# DSC28034 register map
Vendor: Beijing Haawking Technology Co.,Ltd.; File version: 1.0
Registers are 32-bit, read-write, reset 0x0 unless marked. A register's access mark holds for its fields unless they carry their own. Offsets are from the block's base; [hi:lo] are bit positions; {n}, {i} and the like mark numbered series; 'fields as' and 'values as' point back to an identical list.

## AES — AES Accelerator
Base 0x50450000
{0x0+4i} key[{i}] (i=0..3) — 1st-4th word of key
0x10 encrypt_sel — Encryption or decryption select
  [0] encrypt_sel — Select encryption or decryption mode
    0=encryption (Sets encryption mode); 1=decryption (Sets decryption mode)
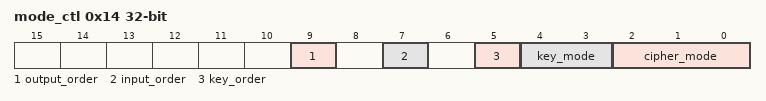
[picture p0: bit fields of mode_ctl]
0x14 mode_ctl — AES mode register
  [9] output_order — Output data order
    0=be (Big Endian); 1=le (Little Endian)
  [7] input_order — Input data order
    0=be (Big Endian); 1=le (Little Endian)
  [5] key_order — Input key order
    0=be (Big Endian); 1=le (Little Endian)
  [4:3] key_mode
    0=AES128; 1=AES192; 2=AES256
  [2:0] cipher_mode
    0=ECB (Electronic Codebook); 1=CBC (Cipher Block Chaining); 2=GCM (Galois/Counter Mode)
{0x18+4i} iv[{i}] (i=0..3) — Initialisation Vector (96 bit for GCM, 128 bit for CBC)
0x28 endian — Endian control
  [0] endian — Input data endian
    0=be (Big Endian); 1=le (Little Endian)
0x2C finish — Finished status
  [0] finish — AES operation finished status
    0=not_finished (Operation not finished); 1=finished (Operation finished)
0x30 dma_sel — DMA select
  [0] dma_sel — Output to DMA if set, to CPU otherwise
0x34 aad_num — GCM additional authenticated data count in bytes, minus one
0x3C pc_num — Plaintext/ciphertext input data count in bytes, minus one
0x40 text_data — Plaintext/ciphertext input data
0x44 aad_data — Additional authenticated data
0x48 tag_chk — Tag check status
  [1:0] tag_chk
    0=busy (Check not finished); 1=fail (Check failed); 2=success (Check success)
0x4C data_in_flag — Data can input flag
  [0] data_in_flag — Data can be written to text_data or aad_data when this flag is set
    0=cannot_input; 1=can_input
{0x50+4i} gcm_in_tag[{i}] (i=0..3) — GCM input tag for comparison with the calculated tag
0x60 out_data — Plaintext/ciphertext output data
0x64 en — AES module enable
  [0] en
    0=Disable module; 1=Enable module
0x68 data_out_flag — Data can output flag
  [0] data_out_flag — Data can be read from out_data when this flag is set
    0=cannot_output (Data cannot output); 1=can_output (Data can output)
0x6C tag_in_flag — Can input tag (when using GCM)
  [0] tag_in_flag — GCM tag can be written to gcm_in_tag when this flag is set
    0=cannot_input; 1=can_input
0x70 tag_clear — Tag clear (a write to this register clears the tag_chk status)
{0x74+4i} gcm_out_tag[{i}] (i=0..3) — Computed GCM output tag
{0x84+4i} key_ext[{i}] (i=0..3) — 5th-8th word of key

## RTC — Real Time Clock
Base 0x50460000
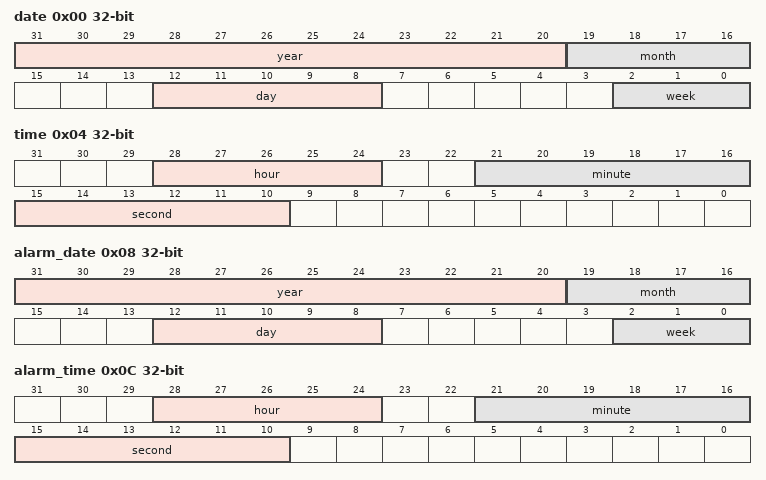
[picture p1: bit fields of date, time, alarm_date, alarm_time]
0x00 date — Timer date information
  [31:20] year range 0..99 — Year. Range [0,99]
  [19:16] month range 1..12 — Month. Range [1,12]
  [12:8] day range 1..31 — Day. Range [1,31] or [1,30] or [1,29] or [1,28]
  [2:0] week range 0..6 — Week. Range [0,6]. 0 is Sunday.
0x04 time — Timer time information
  [28:24] hour range 0..23 — Hour. Range [0,23]
  [21:16] minute range 0..59 — Minute. Range [0,59]
  [15:10] second range 0..59 — Second. Range [0,59]
0x08 alarm_date — Alarm date information
  fields as date
0x0C alarm_time — Alarm time information
  fields as time
0x10 initial_count — Timer counter initial value
  [31:0] count — RTC counter initial value
0x14 current_count — Timer counter current value
  [31:0] count — RTC counter current value
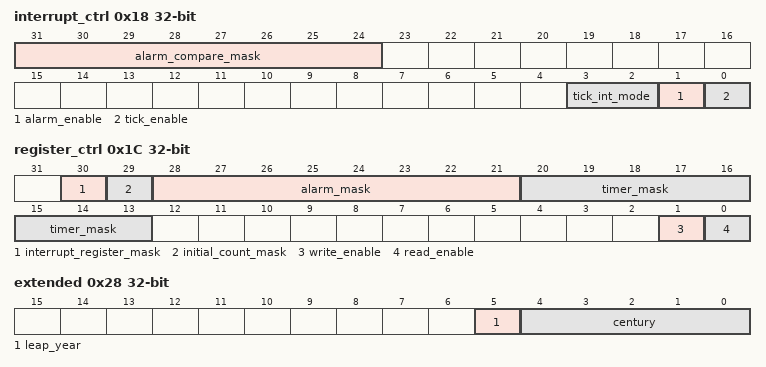
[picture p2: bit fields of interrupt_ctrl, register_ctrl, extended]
0x18 interrupt_ctrl — RTC interrupt settings
  [31:24] alarm_compare_mask — Alarm compare mask for interrupt
  [3:2] tick_int_mode — Tick interrupt enable
  [1] alarm_enable — Alarm interrupt enable
  [0] tick_enable
0x1C register_ctrl — RTC register settings
  [30] interrupt_register_mask — RTC interrupt register mask
  [29] initial_count_mask — RTC counter initial count value mask
  [28:21] alarm_mask — RTC alarm mask
  [20:13] timer_mask — RTC timer mask
  [1] write_enable — RTC timer write enable
  [0] read_enable — RTC timer read enable
0x28 extended — Timer extended information
  [5] leap_year — Is leap year. 1 is leap year, 0 is not leap year
    0=not_leap (0 is not leap year); 1=leap (1 is leap year)
  [4:0] century — Century. Range [0,31]
